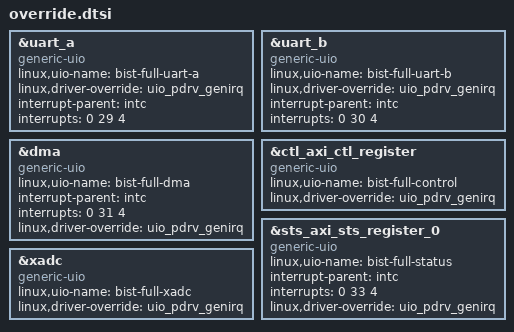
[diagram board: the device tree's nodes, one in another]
&uart_a {
    compatible = "generic-uio";
    linux,uio-name = "bist-full-uart-a";
    linux,driver-override = "uio_pdrv_genirq";
    interrupt-parent = <&intc>;
    interrupts = <0 29 4>;
};
&uart_b {
    compatible = "generic-uio";
    linux,uio-name = "bist-full-uart-b";
    linux,driver-override = "uio_pdrv_genirq";
    interrupt-parent = <&intc>;
    interrupts = <0 30 4>;
};
&dma {
    compatible = "generic-uio";
    linux,uio-name = "bist-full-dma";
    interrupt-parent = <&intc>;
    interrupts = <0 31 4>;
    /delete-property/ interrupt-names;
    linux,driver-override = "uio_pdrv_genirq";
    /delete-node/ dma-channel@40400000;
    /delete-node/ dma-channel@40400030;
};

&ctl_axi_ctl_register {
    compatible = "generic-uio";
    linux,uio-name = "bist-full-control";
    linux,driver-override = "uio_pdrv_genirq";
};
&sts_axi_sts_register_0 {
    compatible = "generic-uio";
    linux,uio-name = "bist-full-status";
    interrupt-parent = <&intc>;
    interrupts = <0 33 4>;
    linux,driver-override = "uio_pdrv_genirq";
};
&xadc {
    compatible = "generic-uio";
    linux,uio-name = "bist-full-xadc";
    linux,driver-override = "uio_pdrv_genirq";
};
